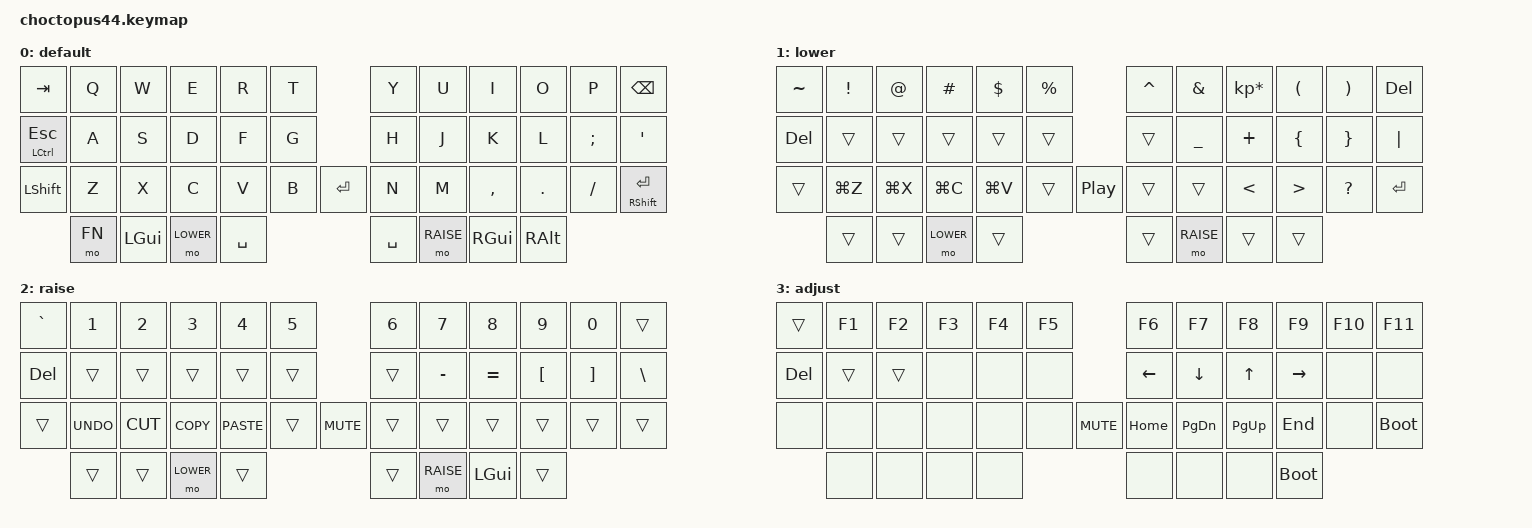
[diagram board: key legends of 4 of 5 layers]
/*
 * Copyright (c) 2021 The ZMK Contributors
 *
 * SPDX-License-Identifier: MIT
 */

#include <behaviors.dtsi>
#include <dt-bindings/zmk/keys.h>
#include <dt-bindings/zmk/bt.h>
#include <dt-bindings/zmk/rgb.h>
#include <dt-bindings/zmk/ext_power.h>
#include <dt-bindings/zmk/outputs.h>

#define BASE 0
#define LOWER 1
#define RAISE 2
#define ADJUST 3
#define FN 4

// Using layer taps on thumbs, having quick tap as well helps w/ repeating space/backspace
&lt { quick_tap_ms = <200>; };

&mt {
    tapping-term-ms = <400>;
};

/ {

 // Activate ADJUST layer by pressing raise and lower
  conditional_layers {
      compatible = "zmk,conditional-layers";
      adjust_layer {
          if-layers = <LOWER RAISE>;
          then-layer = <ADJUST>;
      };
  };

  keymap {
    compatible = "zmk,keymap";


    default_layer {
      label = "default";
      bindings = <
      &kp TAB        &kp Q   &kp W  &kp E    &kp R    &kp T                &kp Y            &kp U          &kp I       &kp O      &kp P         &kp BKSP
      &mt LCTRL ESC  &kp A   &kp S  &kp D    &kp F    &kp G                &kp H            &kp J          &kp K       &kp L      &kp SEMI      &kp QUOT
      &kp LSHFT      &kp Z   &kp X  &kp C    &kp V    &kp B    &kp RET     &kp N            &kp M          &kp COMMA   &kp DOT    &kp FSLH      &mt RSHFT RET
                  &mo FN      &kp LGUI  &mo LOWER   &kp SPACE              &kp SPACE  &mo RAISE  &kp RGUI   &kp RALT
      >;
      sensor-bindings = <&inc_dec_kp UP DOWN>;
    };

    lower_layer {
      label = "lower";
      bindings = <
      &kp TILDE &kp EXCL  &kp AT    &kp HASH    &kp DLLR  &kp PRCNT                     &kp CARET  &kp AMPS       &kp KP_MULTIPLY &kp LPAR        &kp RPAR         &kp DEL
      &kp DEL   &trans    &trans    &trans      &trans    &trans                        &trans     &kp UNDERSCORE &kp PLUS        &kp LEFT_BRACE  &kp RIGHT_BRACE  &kp PIPE
      &trans    &kp LG(Z) &kp LG(X) &kp LG(C)  &kp LG(V)  &trans     &kp C_PLAY_PAUSE   &trans    &trans         &kp LT          &kp GT          &kp QMARK        &kp ENTER
                            &trans     &trans     &mo LOWER  &trans                     &trans  &mo RAISE  &trans   &trans
      >;
      sensor-bindings = <&inc_dec_kp LEFT RIGHT>;
    };

    raise_layer {
      label = "raise";
      bindings = <
        &kp GRAVE  &kp N1      &kp N2    &kp N3      &kp N4      &kp N5                          &kp N6      &kp N7    &kp N8    &kp N9   &kp N0    &trans
        &kp DEL    &trans      &trans    &trans      &trans      &trans                          &trans      &kp MINUS &kp EQUAL &kp LBKT &kp RBKT  &kp BSLH
        &trans     &kp K_UNDO  &kp K_CUT &kp K_COPY  &kp K_PASTE &trans        &kp C_MUTE        &trans      &trans    &trans    &trans   &trans    &trans
                                &trans      &trans      &mo LOWER  &trans                             &trans  &mo RAISE   &kp LGUI  &trans
      >;
      sensor-bindings = <&inc_dec_kp PG_UP PG_DN>;
    };

    adjust_layer {
      label = "adjust";
      bindings = <
        &trans    &kp F1    &kp F2    &kp F3      &kp F4    &kp F5                  &kp F6    &kp F7    &kp F8       &kp F9      &kp F10   &kp F11
        &kp DEL   &trans    &trans    &none       &none     &none                   &kp LEFT  &kp DOWN  &kp UP       &kp RIGHT   &none     &none
        &none     &none     &none     &none       &none     &none     &kp C_MUTE    &kp HOME  &kp PG_DN &kp PG_UP    &kp END     &none     &bootloader
                              &none       &none     &none    &none                           &none    &none     &none     &bootloader
      >;
      sensor-bindings = <&inc_dec_kp C_VOL_DN C_VOL_UP>;
    };

    fn_layer {
        label = "fn";
        bindings = <
          &bt BT_CLR     &bt BT_SEL 0   &bt BT_SEL 1  &bt BT_SEL 2  &bt BT_SEL 3    &bt BT_SEL 4                   &none            &none         &none         &none            &none          &kp C_VOLUME_UP
          &out OUT_USB   &out OUT_BLE   &out OUT_TOG  &none           &none                          &kp LG(LBRC)     &kp LG(MINUS) &kp LG(EQUAL) &kp LG(RBRC)     &none          &kp C_VOLUME_DOWN
          &none        &kp HASH      &none         &none         &none           &none         &kp C_MUTE       &kp LG(LBKT)     &kp LG(RBKT)  &kp LG(GRAVE) &kp LG(LBKT)     &kp LG(RBKT)   &kp K_MUTE
                                     &trans        &kp BSPC      &kp ENTER       &none                           &none     &kp C_PREV            &kp C_PLAY_PAUSE         &kp C_NEXT
        >;
        sensor-bindings = <&inc_dec_kp C_VOL_DN C_VOL_UP>;
    };

  };
};
